AUTOSAR XML (schema 4-2-2)
package /ComponentTypes
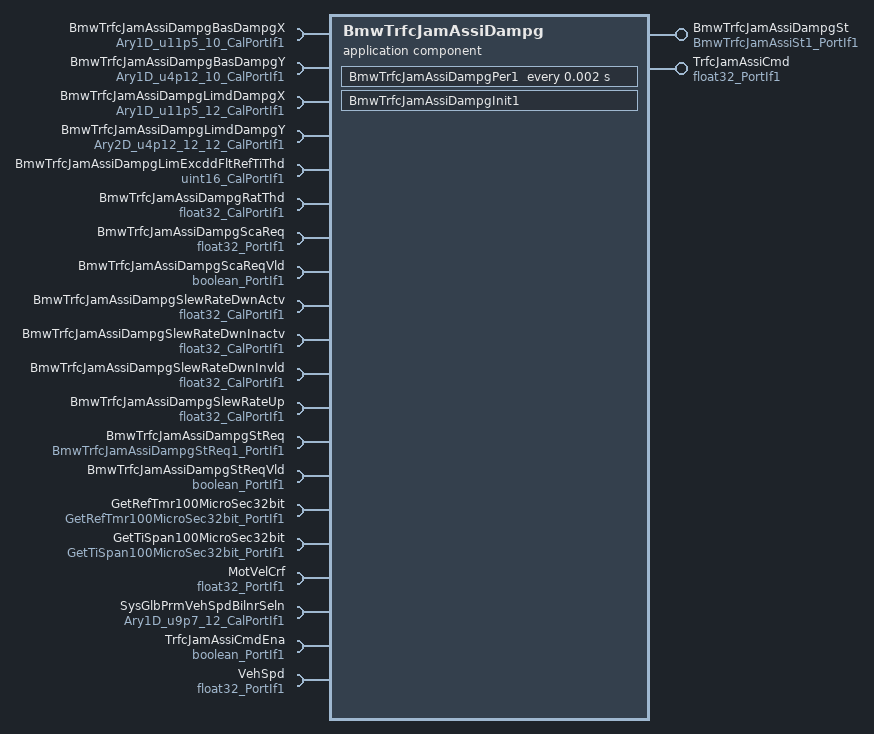
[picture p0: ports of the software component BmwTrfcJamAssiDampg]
  application sw component type BmwTrfcJamAssiDampg
    provide port BmwTrfcJamAssiDampgSt: nonqueued-sender-com-spec{data-element=Val, init-value=1}, provided-interface=BmwTrfcJamAssiSt1_PortIf1
    provide port TrfcJamAssiCmd: nonqueued-sender-com-spec{data-element=Val, init-value=0}, provided-interface=float32_PortIf1
    20 x require port:
      BmwTrfcJamAssiDampgBasDampgX: parameter-require-com-spec{init-value=[0, 960, 1920, 2880, 3840, 4800, 5760, 6720, 7680, 9600], parameter=Ary1D}, required-interface=Ary1D_u11p5_10_CalPortIf1
      BmwTrfcJamAssiDampgBasDampgY: parameter-require-com-spec{init-value=10 x 0, parameter=Ary1D}, required-interface=Ary1D_u4p12_10_CalPortIf1
      BmwTrfcJamAssiDampgLimdDampgX: parameter-require-com-spec{init-value=[0, 873, 1745, 2618, 3491, 4364, 5236, 6109, 6982, 7855, 8727, 9600], parameter=Ary1D}, required-interface=Ary1D_u11p5_12_CalPortIf1
      BmwTrfcJamAssiDampgLimdDampgY: parameter-require-com-spec{init-value=12 x 12 x 36045, parameter=Ary2D}, required-interface=Ary2D_u4p12_12_12_CalPortIf1
      BmwTrfcJamAssiDampgLimExcddFltRefTiThd: parameter-require-com-spec{init-value=10, parameter=Val}, required-interface=uint16_CalPortIf1
      BmwTrfcJamAssiDampgRatThd: parameter-require-com-spec{init-value=0.9, parameter=Val}, required-interface=float32_CalPortIf1
      BmwTrfcJamAssiDampgScaReq: nonqueued-receiver-com-spec{data-element=Val, filter=data-filter-type=ALWAYS, init-value=0}, required-interface=float32_PortIf1
      BmwTrfcJamAssiDampgScaReqVld: nonqueued-receiver-com-spec{data-element=Logl, filter=data-filter-type=ALWAYS, init-value=0}, required-interface=boolean_PortIf1
      BmwTrfcJamAssiDampgSlewRateDwnActv: parameter-require-com-spec{init-value=1000, parameter=Val}, required-interface=float32_CalPortIf1
      BmwTrfcJamAssiDampgSlewRateDwnInactv: parameter-require-com-spec{init-value=1000, parameter=Val}, required-interface=float32_CalPortIf1
      BmwTrfcJamAssiDampgSlewRateDwnInvld: parameter-require-com-spec{init-value=1000, parameter=Val}, required-interface=float32_CalPortIf1
      BmwTrfcJamAssiDampgSlewRateUp: parameter-require-com-spec{init-value=1000, parameter=Val}, required-interface=float32_CalPortIf1
      BmwTrfcJamAssiDampgStReq: nonqueued-receiver-com-spec{data-element=Val, filter=data-filter-type=ALWAYS, init-value=1}, required-interface=BmwTrfcJamAssiDampgStReq1_PortIf1
      BmwTrfcJamAssiDampgStReqVld: nonqueued-receiver-com-spec{data-element=Logl, filter=data-filter-type=ALWAYS, init-value=0}, required-interface=boolean_PortIf1
      GetRefTmr100MicroSec32bit: client-com-spec=Oper, required-interface=GetRefTmr100MicroSec32bit_PortIf1
      GetTiSpan100MicroSec32bit: client-com-spec=Oper, required-interface=GetTiSpan100MicroSec32bit_PortIf1
      MotVelCrf: nonqueued-receiver-com-spec{data-element=Val, filter=data-filter-type=ALWAYS, init-value=0}, required-interface=float32_PortIf1
      SysGlbPrmVehSpdBilnrSeln: parameter-require-com-spec{init-value=[0, 640, 1920, 3840, 7680, 10240, 12800, 15360, 19200, 23040, 25600, 28160], parameter=Ary1D}, required-interface=Ary1D_u9p7_12_CalPortIf1
      TrfcJamAssiCmdEna: nonqueued-receiver-com-spec{data-element=Logl, filter=data-filter-type=ALWAYS, init-value=1}, required-interface=boolean_PortIf1
      VehSpd: nonqueued-receiver-com-spec{data-element=Val, filter=data-filter-type=ALWAYS, init-value=0}, required-interface=float32_PortIf1
    behavior BmwTrfcJamAssiDampg_InternalBehavior
      ar-typed-per-instance-memorys:
        4 x data, all with sw-calibration-access=READ-ONLY:
          BmwTrfcJamAssiDampgScaStVari: type=float32
          LimExcddFltRefTi: type=uint32
          PrevLimExcddFlt: type=boolean
          TmpBmwTrfcJamAssiDampgSt: type=uint8
      init event BmwTrfcJamAssiDampg_InitEvent: start-on-event=BmwTrfcJamAssiDampgInit1
      timing event TMT_BmwTrfcJamAssiDampgPer1: start-on-event=BmwTrfcJamAssiDampgPer1, period=0.002
      port-api-options:
        enable-take-address=false, error-handling=NO-TRANSFORMER-ERROR-HANDLING, indirect-api=false, port=BmwTrfcJamAssiDampgBasDampgX
        enable-take-address=false, error-handling=NO-TRANSFORMER-ERROR-HANDLING, indirect-api=false, port=BmwTrfcJamAssiDampgBasDampgY
        enable-take-address=false, error-handling=NO-TRANSFORMER-ERROR-HANDLING, indirect-api=false, port=BmwTrfcJamAssiDampgLimdDampgX
        enable-take-address=false, error-handling=NO-TRANSFORMER-ERROR-HANDLING, indirect-api=false, port=BmwTrfcJamAssiDampgLimdDampgY
        enable-take-address=false, error-handling=NO-TRANSFORMER-ERROR-HANDLING, indirect-api=false, port=BmwTrfcJamAssiDampgLimExcddFltRefTiThd
        enable-take-address=false, error-handling=NO-TRANSFORMER-ERROR-HANDLING, indirect-api=false, port=BmwTrfcJamAssiDampgRatThd
        enable-take-address=false, error-handling=NO-TRANSFORMER-ERROR-HANDLING, indirect-api=false, port=BmwTrfcJamAssiDampgScaReq
        enable-take-address=false, error-handling=NO-TRANSFORMER-ERROR-HANDLING, indirect-api=false, port=BmwTrfcJamAssiDampgScaReqVld
        enable-take-address=false, error-handling=NO-TRANSFORMER-ERROR-HANDLING, indirect-api=false, port=BmwTrfcJamAssiDampgSlewRateDwnActv
        enable-take-address=false, error-handling=NO-TRANSFORMER-ERROR-HANDLING, indirect-api=false, port=BmwTrfcJamAssiDampgSlewRateDwnInactv
        enable-take-address=false, error-handling=NO-TRANSFORMER-ERROR-HANDLING, indirect-api=false, port=BmwTrfcJamAssiDampgSlewRateDwnInvld
        enable-take-address=false, error-handling=NO-TRANSFORMER-ERROR-HANDLING, indirect-api=false, port=BmwTrfcJamAssiDampgSlewRateUp
        enable-take-address=false, error-handling=NO-TRANSFORMER-ERROR-HANDLING, indirect-api=false, port=BmwTrfcJamAssiDampgSt
        enable-take-address=false, error-handling=NO-TRANSFORMER-ERROR-HANDLING, indirect-api=false, port=BmwTrfcJamAssiDampgStReq
        enable-take-address=false, error-handling=NO-TRANSFORMER-ERROR-HANDLING, indirect-api=false, port=BmwTrfcJamAssiDampgStReqVld
        enable-take-address=false, error-handling=NO-TRANSFORMER-ERROR-HANDLING, indirect-api=false, port=GetRefTmr100MicroSec32bit
        enable-take-address=false, error-handling=NO-TRANSFORMER-ERROR-HANDLING, indirect-api=false, port=GetTiSpan100MicroSec32bit
        enable-take-address=false, error-handling=NO-TRANSFORMER-ERROR-HANDLING, indirect-api=false, port=MotVelCrf
        enable-take-address=false, error-handling=NO-TRANSFORMER-ERROR-HANDLING, indirect-api=false, port=SysGlbPrmVehSpdBilnrSeln
        enable-take-address=false, error-handling=NO-TRANSFORMER-ERROR-HANDLING, indirect-api=false, port=TrfcJamAssiCmd
        enable-take-address=false, error-handling=NO-TRANSFORMER-ERROR-HANDLING, indirect-api=false, port=TrfcJamAssiCmdEna
        enable-take-address=false, error-handling=NO-TRANSFORMER-ERROR-HANDLING, indirect-api=false, port=VehSpd
      runnable BmwTrfcJamAssiDampgInit1
      runnable BmwTrfcJamAssiDampgPer1
        data-receive-point-by-arguments:
          7 x access:
            REC_BmwTrfcJamAssiDampgScaReq_Val: accessed-variable=BmwTrfcJamAssiDampgScaReq.Val
            REC_BmwTrfcJamAssiDampgScaReqVld_Logl: accessed-variable=BmwTrfcJamAssiDampgScaReqVld.Logl
            REC_BmwTrfcJamAssiDampgStReq_Val: accessed-variable=BmwTrfcJamAssiDampgStReq.Val
            REC_BmwTrfcJamAssiDampgStReqVld_Logl: accessed-variable=BmwTrfcJamAssiDampgStReqVld.Logl
            REC_MotVelCrf_Val: accessed-variable=MotVelCrf.Val
            REC_TrfcJamAssiCmdEna_Logl: accessed-variable=TrfcJamAssiCmdEna.Logl
            SEND_VehSpd_Val: accessed-variable=VehSpd.Val
        data-send-points:
          access SEND_BmwTrfcJamAssiDampgSt_Val: accessed-variable=BmwTrfcJamAssiDampgSt.Val
          access SEND_TrfcJamAssiCmd_Val: accessed-variable=TrfcJamAssiCmd.Val
        sync call SC_GetRefTmr100MicroSec32bit_Oper: operation=GetRefTmr100MicroSec32bit.Oper, timeout=0
        sync call SC_GetTiSpan100MicroSec32bit_Oper: operation=GetTiSpan100MicroSec32bit.Oper, timeout=0
  swc implementation BmwTrfcJamAssiDampg_Implementation: behavior=BmwTrfcJamAssiDampg_InternalBehavior
    code-descriptors:
      code Default: artifact-descriptors=autosar-engineering-object={short-label=Default, category=SWSRC}
